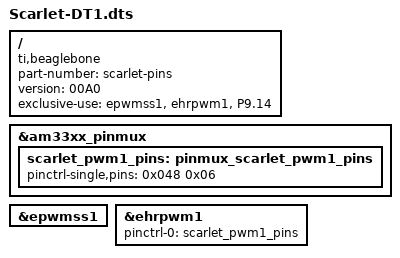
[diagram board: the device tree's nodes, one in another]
/dts-v1/;
/plugin/;

/ {
    /* Generated by Scarlet. */
    compatible = "ti,beaglebone", "ti,beaglebone-black";
    part-number = "scarlet-pins";
    version = "00A0";
    
    exclusive-use =
        "epwmss1",
        "ehrpwm1",
        "P9.14";
    
    fragment@2 {
        target = <&am33xx_pinmux>;
        __overlay__ {
            scarlet_pwm1_pins: pinmux_scarlet_pwm1_pins {
                pinctrl-single,pins = <
                    0x048 0x06
                >;
            };
        };
    };
    
    fragment@12 {
        target = <&epwmss1>;
        __overlay__ {
            status = "okay";
            pinctrl-names = "default";
        };
    };
    fragment@13 {
        target = <&ehrpwm1>;
        __overlay__ {
            status = "okay";
            pinctrl-names = "default";
            pinctrl-0 = <&scarlet_pwm1_pins>;
        };
    };
    
};
